# max32665 register map
Vendor: Maxim-Integrated; Series: ARMCM3; File version: 1.1
CPU: CM4 r2p1, little endian, MPU, FPU, 3 interrupt priority bits
Registers are 32-bit, read-write, reset 0x0 unless marked. A register's access mark holds for its fields unless they carry their own. Offsets are from the block's base; [hi:lo] are bit positions.

## SIR — System Initialization Registers.
Base 0x40000400
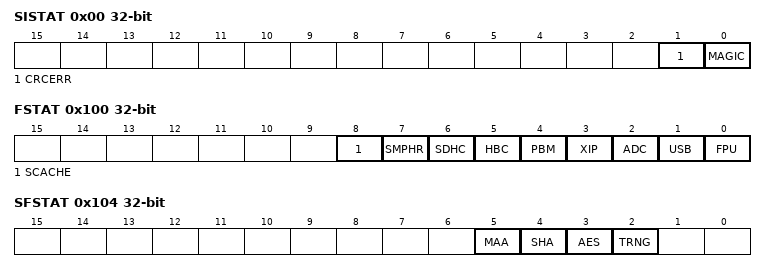
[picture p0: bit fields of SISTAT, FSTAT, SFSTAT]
0x00 SISTAT ro — System Initialization Status Register.
  [1] CRCERR — CRC Error Status. This bit is set by the system initialization block following power-up.
    on read: 0=noError (No CRC errors occurred during the read of the OTP memory block.); 1=error (A CRC error occurred while reading the OTP. The address of the failure location in the OTP memory is stored in the ERRADDR register.)
  [0] MAGIC — Magic Word Validation. This bit is set by the system initialization block following power-up.
    on read: 0=magicNotSet (Magic word was not set (OTP has not been initialized properly).); 1=magicSet (Magic word was set (OTP contains valid settings).)
0x04 ERRADDR ro — Read-only field set by the SIB block if a CRC error occurs during the read of the OTP memory. Contains the failing address in OTP memory (when CRCERR equals 1).
0x54 BTLE_LDO_TRIM_TX — BTLE LDO TX Trim register.
  [4:0] TX — TX LDO trim value.
0x5C BTLE_LDO_TRIM_RX — BTLE LDO RX Trim register.
  [4:0] RX — RX LDO trim value.
0x100 FSTAT ro — funcstat register.
  [all] fields
    0=no; 1=yes
  [8] SCACHE — System Cache function.
  [7] SMPHR — SMPHR function.
  [6] SDHC — SDHC function.
  [5] HBC — HBC function.
  [4] PBM — PBM function.
  [3] XIP — XiP function.
  [2] ADC — 10-bit Sigma Delta ADC.
  [1] USB — USB Device.
  [0] FPU — FPU Function.
0x104 SFSTAT ro — secfuncstat register.
  [all] fields
    0=no; 1=yes
  [5] MAA — MAA function.
  [4] SHA — SHA function.
  [3] AES — AES function.
  [2] TRNG — TRNG function.

## SPIXFC_FIFO — SPI XiP Master Controller FIFO.
Base 0x400BC000
0x00 TX_8 8-bit — SPI TX FIFO 8-Bit Write
0x00 TX_16 16-bit (alternate view of TX_8) — SPI TX FIFO 16-Bit Write
0x00 TX_32 (alternate view of TX_8) — SPI TX FIFO 32-Bit Write
0x04 RX_8 8-bit — SPI RX FIFO 8-Bit Access
0x04 RX_16 16-bit (alternate view of RX_8) — SPI RX FIFO 16-Bit Access
0x04 RX_32 (alternate view of RX_8) — SPI RX FIFO 32-Bit Access

## SRCC — External Memory Cache Controller Registers.
Base 0x40033000
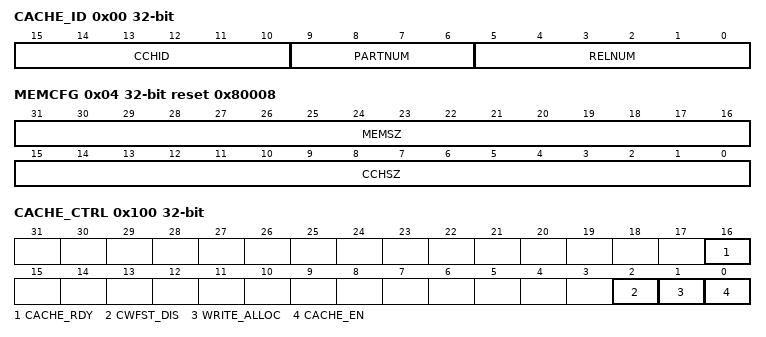
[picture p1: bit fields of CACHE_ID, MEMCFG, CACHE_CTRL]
0x00 CACHE_ID ro
  [15:10] CCHID — Cache ID. This field reflects the value of the C_ID_CACHEID configuration parameter.
  [9:6] PARTNUM — Part Number. This field reflects the value of C_ID_PART_NUMBER configuration parameter.
  [5:0] RELNUM — Release Number. Identifies the RTL release version.
0x04 MEMCFG ro reset 0x80008 — Memory Configuration Register.
  [31:16] MEMSZ — Main Memory Size. Indicates the total size, in units of 128 Kbytes, of code memory accessible to the cache controller.
  [15:0] CCHSZ — Cache Size. Indicates total size in Kbytes of cache.
0x100 CACHE_CTRL — Cache Control and Status Register.
  [16] CACHE_RDY — Cache Ready flag. Cleared by hardware when at any time the cache as a whole is invalidated (including a system reset). When this bit is 0, the cache is effectively in bypass mode (instruction fetches will come from main memory or from the line fill buffer). Set by hardware when the invalidate operation is complete and the cache is ready.
    0=notReady; 1=ready
  [2] CWFST_DIS — Critical word first and streaming disable. This bit only writeable while the cache is disabled.
    1=dis (Critical word first and streaming disabled.); 0=en (Critical word first and streaming enabled.)
  [1] WRITE_ALLOC — Write Allocate Enable. This bit only writable while the cache is disabled.
    0=dis (Write-no-allocate.); 1=en (Write-allocate enabled.)
  [0] CACHE_EN — Cache Enable. Controls whether the cache is bypassed or is in use. Changing the state of this bit will cause the instruction cache to be flushed and its contents invalidated.
    0=dis (Cache Bypassed. Instruction data is stored in the line fill buffer but is not written to main cache memory array.); 1=en (Cache Enabled.)
0x700 INVALIDATE — Invalidate All Cache Contents. Any time this register location is written (regardless of the data value), the cache controller immediately begins invalidating the entire contents of the cache memory. The cache will be in bypass mode until the invalidate operation is complete. System software can examine the Cache Ready bit (CACHE_CTRL.CACHE_RDY) to determine when the invalidate operation is complete. Note that it is not necessary to disable the cache controller prior to beginning this operation. Reads from this register always return 0.
  [31:0] IA — Invalidate all cache contents.
